VERSION ""

NS_ :

BS_:

BU_:

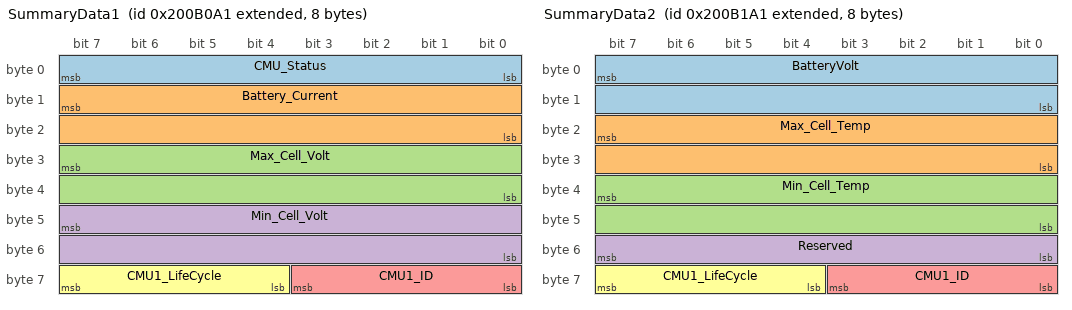
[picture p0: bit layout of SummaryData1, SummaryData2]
BO_ 2181083297 SummaryData1: 8 Vector__XXX
 SG_ CMU_Status : 0|8@1+ (1,0) [0|0] "" Vector__XXX
 SG_ Battery_Current : 15|16@0- (0.02,0) [-500|500] "A" Vector__XXX
 SG_ Max_Cell_Volt : 31|16@0+ (0.001,0) [0|5] "V" Vector__XXX
 SG_ Min_Cell_Volt : 47|16@0+ (0.001,0) [0|5] "V" Vector__XXX
 SG_ CMU1_ID : 56|4@1+ (1,0) [0|0] "" Vector__XXX
 SG_ CMU1_LifeCycle : 60|4@1+ (1,0) [0|15] "" Vector__XXX

BO_ 2181083553 SummaryData2: 8 Vector__XXX
 SG_ BatteryVolt : 7|16@0+ (0.01,0) [0|500] "V" Vector__XXX
 SG_ Max_Cell_Temp : 23|16@0+ (0.1,-40) [-40|210] "C" Vector__XXX
 SG_ Min_Cell_Temp : 39|16@0+ (0.1,-40) [-40|210] "C" Vector__XXX
 SG_ Reserved : 48|8@1+ (1,0) [0|0] "" Vector__XXX
 SG_ CMU1_ID : 56|4@1+ (1,0) [0|0] "" Vector__XXX
 SG_ CMU1_LifeCycle : 60|4@1+ (1,0) [0|15] "" Vector__XXX

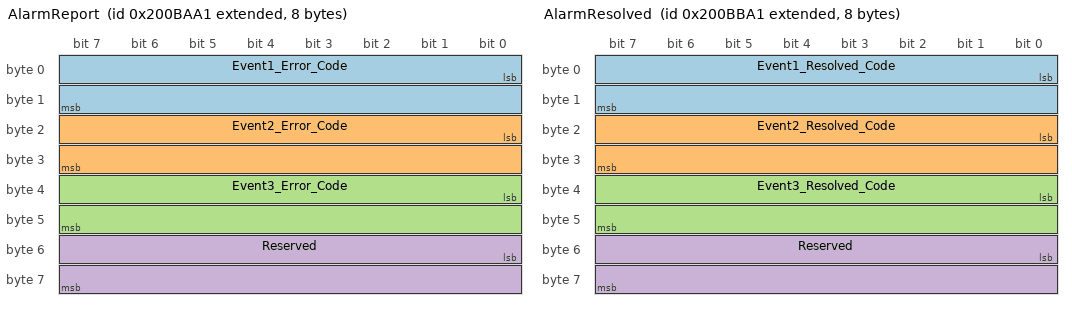
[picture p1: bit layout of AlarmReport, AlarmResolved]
BO_ 2181085857 AlarmReport: 8 Vector__XXX
 SG_ Event1_Error_Code : 0|16@1+ (1,0) [0|0] "" Vector__XXX
 SG_ Event2_Error_Code : 16|16@1+ (1,0) [0|0] "" Vector__XXX
 SG_ Event3_Error_Code : 32|16@1+ (1,0) [0|0] "" Vector__XXX
 SG_ Reserved : 48|16@1+ (1,0) [0|0] "" Vector__XXX

BO_ 2181086113 AlarmResolved: 8 Vector__XXX
 SG_ Event1_Resolved_Code : 0|16@1+ (1,0) [0|0] "" Vector__XXX
 SG_ Event2_Resolved_Code : 16|16@1+ (1,0) [0|0] "" Vector__XXX
 SG_ Event3_Resolved_Code : 32|16@1+ (1,0) [0|0] "" Vector__XXX
 SG_ Reserved : 48|16@1+ (1,0) [0|0] "" Vector__XXX

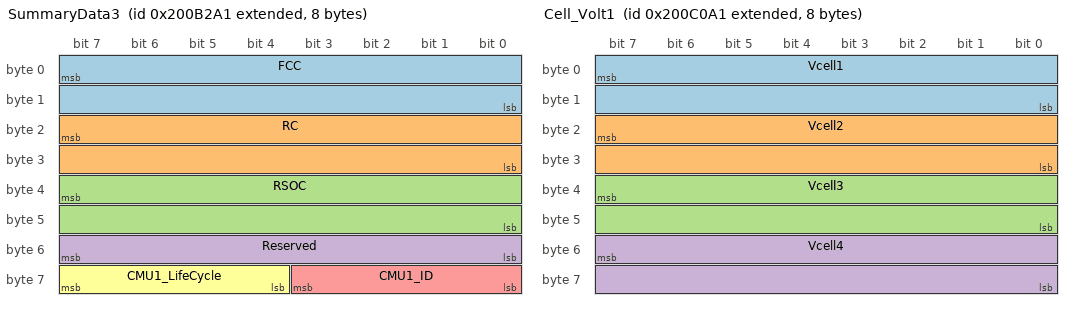
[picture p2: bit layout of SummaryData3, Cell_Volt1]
BO_ 2181083809 SummaryData3: 8 Vector__XXX
 SG_ FCC : 7|16@0+ (0.01,0) [0|500] "Ah" Vector__XXX
 SG_ RC : 23|16@0+ (0.01,0) [0|500] "Ah" Vector__XXX
 SG_ RSOC : 39|16@0+ (0.1,-50) [-50|150] "%" Vector__XXX
 SG_ Reserved : 48|8@1+ (1,0) [0|0] "" Vector__XXX
 SG_ CMU1_ID : 56|4@1+ (1,0) [0|15] "" Vector__XXX
 SG_ CMU1_LifeCycle : 60|4@1+ (1,0) [0|0] "" Vector__XXX

BO_ 2181087393 Cell_Volt1: 8 Vector__XXX
 SG_ Vcell1 : 7|16@0+ (0.001,0) [0|0] "" Vector__XXX
 SG_ Vcell2 : 23|16@0+ (0.001,0) [0|0] "" Vector__XXX
 SG_ Vcell3 : 39|16@0+ (0.001,0) [0|0] "" Vector__XXX
 SG_ Vcell4 : 55|16@0+ (0.001,0) [0|0] "" Vector__XXX

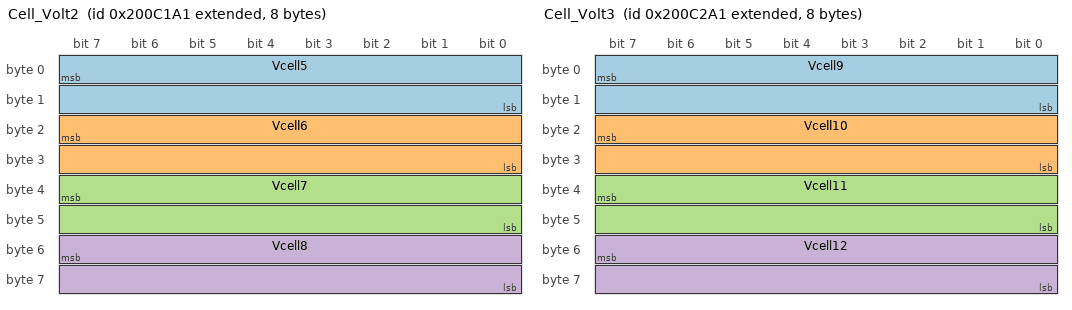
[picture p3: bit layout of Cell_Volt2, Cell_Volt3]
BO_ 2181087649 Cell_Volt2: 8 Vector__XXX
 SG_ Vcell5 : 7|16@0+ (0.001,0) [0|0] "" Vector__XXX
 SG_ Vcell6 : 23|16@0+ (0.001,0) [0|0] "" Vector__XXX
 SG_ Vcell7 : 39|16@0+ (0.001,0) [0|0] "" Vector__XXX
 SG_ Vcell8 : 55|16@0+ (0.001,0) [0|0] "" Vector__XXX

BO_ 2181087905 Cell_Volt3: 8 Vector__XXX
 SG_ Vcell9 : 7|16@0+ (0.001,0) [0|0] "" Vector__XXX
 SG_ Vcell10 : 23|16@0+ (0.001,0) [0|0] "" Vector__XXX
 SG_ Vcell11 : 39|16@0+ (0.001,0) [0|0] "" Vector__XXX
 SG_ Vcell12 : 55|16@0+ (0.001,0) [0|0] "" Vector__XXX

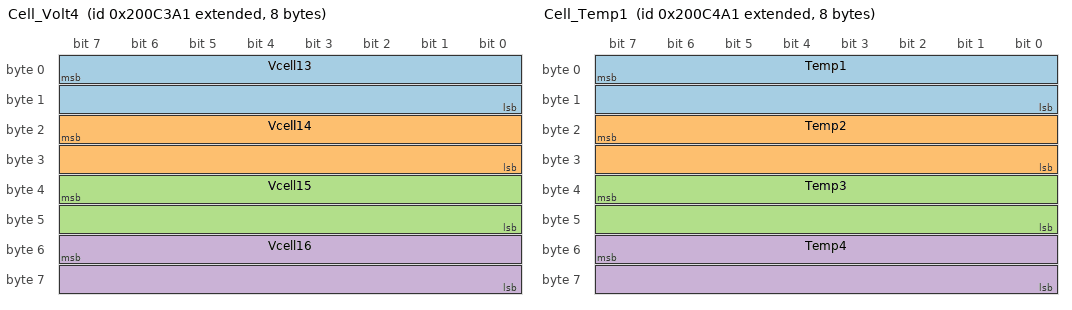
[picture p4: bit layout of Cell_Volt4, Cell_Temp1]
BO_ 2181088161 Cell_Volt4: 8 Vector__XXX
 SG_ Vcell13 : 7|16@0+ (0.001,0) [0|0] "" Vector__XXX
 SG_ Vcell14 : 23|16@0+ (0.001,0) [0|0] "" Vector__XXX
 SG_ Vcell15 : 39|16@0+ (0.001,0) [0|0] "" Vector__XXX
 SG_ Vcell16 : 55|16@0+ (0.001,0) [0|0] "" Vector__XXX

BO_ 2181088417 Cell_Temp1: 8 Vector__XXX
 SG_ Temp1 : 7|16@0+ (0.1,-40) [0|0] "" Vector__XXX
 SG_ Temp2 : 23|16@0+ (0.1,-40) [0|0] "" Vector__XXX
 SG_ Temp3 : 39|16@0+ (0.1,-40) [0|0] "" Vector__XXX
 SG_ Temp4 : 55|16@0+ (0.1,-40) [0|0] "" Vector__XXX

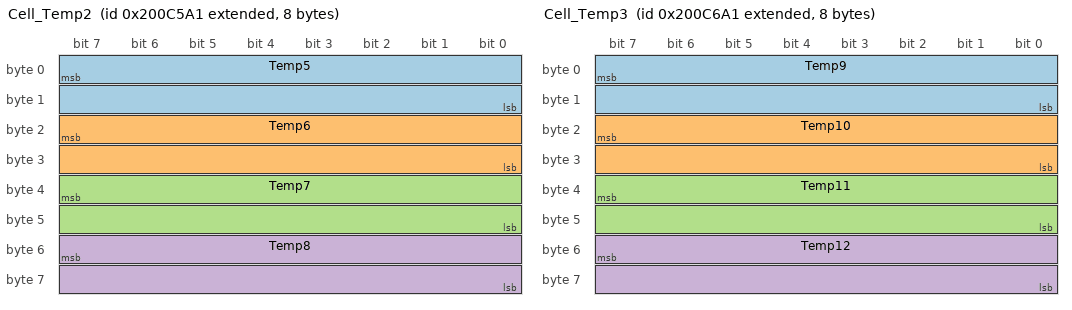
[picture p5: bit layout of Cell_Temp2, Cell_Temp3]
BO_ 2181088673 Cell_Temp2: 8 Vector__XXX
 SG_ Temp5 : 7|16@0+ (0.1,-40) [0|0] "" Vector__XXX
 SG_ Temp6 : 23|16@0+ (0.1,-40) [0|0] "" Vector__XXX
 SG_ Temp7 : 39|16@0+ (0.1,-40) [0|0] "" Vector__XXX
 SG_ Temp8 : 55|16@0+ (0.1,-40) [0|0] "" Vector__XXX

BO_ 2181088929 Cell_Temp3: 8 Vector__XXX
 SG_ Temp9 : 7|16@0+ (0.1,-40) [0|0] "" Vector__XXX
 SG_ Temp10 : 23|16@0+ (0.1,-40) [0|0] "" Vector__XXX
 SG_ Temp11 : 39|16@0+ (0.1,-40) [0|0] "" Vector__XXX
 SG_ Temp12 : 55|16@0+ (0.1,-40) [0|0] "" Vector__XXX

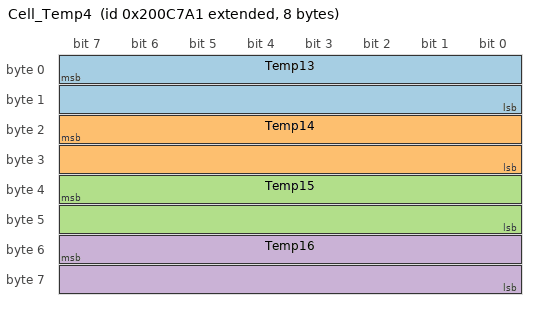
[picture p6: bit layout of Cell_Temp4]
BO_ 2181089185 Cell_Temp4: 8 Vector__XXX
 SG_ Temp13 : 7|16@0+ (0.1,-40) [0|0] "" Vector__XXX
 SG_ Temp14 : 23|16@0+ (0.1,-40) [0|0] "" Vector__XXX
 SG_ Temp15 : 39|16@0+ (0.1,-40) [0|0] "" Vector__XXX
 SG_ Temp16 : 55|16@0+ (0.1,-40) [0|0] "" Vector__XXX
